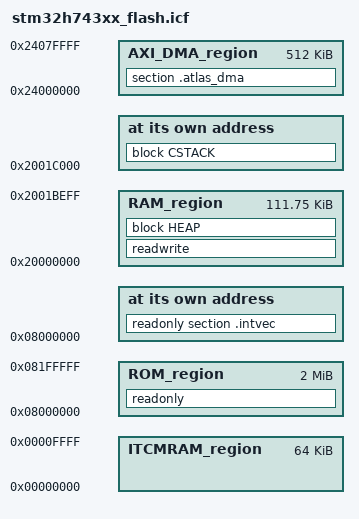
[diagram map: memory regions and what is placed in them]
/*###ICF### Section handled by ICF editor, don't touch! ****/
/*-Editor annotation file-*/
/* IcfEditorFile="$TOOLKIT_DIR$\config\ide\IcfEditor\cortex_v1_0.xml" */
/*-Specials-*/
define symbol __ICFEDIT_intvec_start__ = 0x08000000;
/*-Memory Regions-*/
define symbol __ICFEDIT_region_ROM_start__     = 0x08000000;
define symbol __ICFEDIT_region_ROM_end__       = 0x081FFFFF;
define symbol __ICFEDIT_region_RAM_start__     = 0x20000000;
define symbol __ICFEDIT_region_RAM_end__       = 0x2001FFFF;
define symbol __ICFEDIT_region_ITCMRAM_start__ = 0x00000000;
define symbol __ICFEDIT_region_ITCMRAM_end__   = 0x0000FFFF;
/*-Sizes-*/
define symbol __ICFEDIT_size_cstack__ = 0x4000;
define symbol __ICFEDIT_size_heap__   = 0x0;
/**** End of ICF editor section. ###ICF###*/


define memory mem with size = 4G;
/* Match GNU's MSP and MPU_Config's 256-byte guard. Never put ordinary
   readwrite data in the guard or leave CSTACK placement to linker heuristics. */
define symbol __atlas_msp_start__ = 0x2001C000;
define symbol __atlas_msp_guard_start__ = 0x2001BF00;
define region ROM_region      = mem:[from __ICFEDIT_region_ROM_start__   to __ICFEDIT_region_ROM_end__];
define region RAM_region      = mem:[from __ICFEDIT_region_RAM_start__   to (__atlas_msp_guard_start__ - 1)];
define region AXI_DMA_region  = mem:[from 0x24000000 to 0x2407FFFF];
define region ITCMRAM_region  = mem:[from __ICFEDIT_region_ITCMRAM_start__ to __ICFEDIT_region_ITCMRAM_end__];

define block CSTACK    with alignment = 8, size = __ICFEDIT_size_cstack__   { };
define block HEAP      with alignment = 8, size = __ICFEDIT_size_heap__     { };

initialize by copy { readwrite };
do not initialize  { section .noinit, section .atlas_dma };
place in AXI_DMA_region { section .atlas_dma };
place at address mem:__atlas_msp_start__ { block CSTACK };

place at address mem:__ICFEDIT_intvec_start__ { readonly section .intvec };

place in ROM_region   { readonly };
place in RAM_region   { readwrite,
                        block HEAP };
